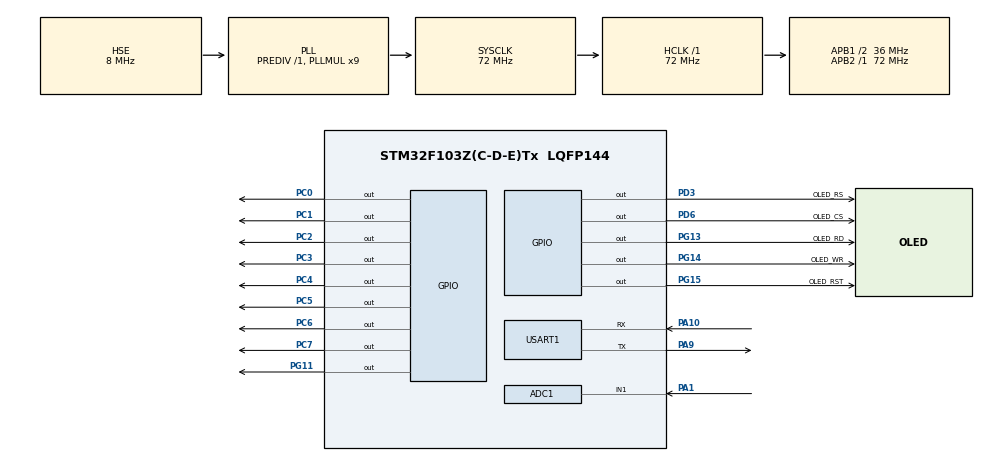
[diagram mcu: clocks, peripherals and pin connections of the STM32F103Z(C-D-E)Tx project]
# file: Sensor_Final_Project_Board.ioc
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ADC1.Channel-0\#ChannelRegularConversion=ADC_CHANNEL_1
ADC1.NbrOfConversionFlag=1
ADC1.Rank-0\#ChannelRegularConversion=1
ADC1.SamplingTime-0\#ChannelRegularConversion=ADC_SAMPLETIME_239CYCLES_5
ADC1.master=1
Mcu.Family=STM32F1
Mcu.Name=STM32F103Z(C-D-E)Tx
Mcu.Package=LQFP144
NVIC.PriorityGroup=NVIC_PRIORITYGROUP_4
NVIC.TIM2_IRQn=true\:0\:0\:false\:false\:true\:true\:true\:true
OSC_IN.Mode=HSE-External-Oscillator
OSC_IN.Signal=RCC_OSC_IN
OSC_OUT.Mode=HSE-External-Oscillator
OSC_OUT.Signal=RCC_OSC_OUT
PA1.Signal=ADCx_IN1
PA10.Mode=Asynchronous
PA10.Signal=USART1_RX
PA13.Mode=Serial_Wire
PA13.Signal=SYS_JTMS-SWDIO
PA14.Mode=Serial_Wire
PA14.Signal=SYS_JTCK-SWCLK
PA9.Mode=Asynchronous
PA9.Signal=USART1_TX
PC0.GPIO_Speed=GPIO_SPEED_FREQ_HIGH
PC0.PinState=GPIO_PIN_SET
PC0.Signal=GPIO_Output
PC1.GPIO_Speed=GPIO_SPEED_FREQ_HIGH
PC1.PinState=GPIO_PIN_SET
PC1.Signal=GPIO_Output
PC14-OSC32_IN.Mode=LSE-External-Oscillator
PC14-OSC32_IN.Signal=RCC_OSC32_IN
PC15-OSC32_OUT.Mode=LSE-External-Oscillator
PC15-OSC32_OUT.Signal=RCC_OSC32_OUT
PC2.GPIO_Speed=GPIO_SPEED_FREQ_HIGH
PC2.PinState=GPIO_PIN_SET
PC2.Signal=GPIO_Output
PC3.GPIO_Speed=GPIO_SPEED_FREQ_HIGH
PC3.PinState=GPIO_PIN_SET
PC3.Signal=GPIO_Output
PC4.GPIO_Speed=GPIO_SPEED_FREQ_HIGH
PC4.PinState=GPIO_PIN_SET
PC4.Signal=GPIO_Output
PC5.GPIO_Speed=GPIO_SPEED_FREQ_HIGH
PC5.PinState=GPIO_PIN_SET
PC5.Signal=GPIO_Output
PC6.GPIO_Speed=GPIO_SPEED_FREQ_HIGH
PC6.PinState=GPIO_PIN_SET
PC6.Signal=GPIO_Output
PC7.GPIO_Speed=GPIO_SPEED_FREQ_HIGH
PC7.PinState=GPIO_PIN_SET
PC7.Signal=GPIO_Output
PD3.GPIO_Label=OLED_RS
PD3.GPIO_Speed=GPIO_SPEED_FREQ_HIGH
PD3.PinState=GPIO_PIN_SET
PD3.Signal=GPIO_Output
PD6.GPIO_Label=OLED_CS
PD6.GPIO_Speed=GPIO_SPEED_FREQ_HIGH
PD6.PinState=GPIO_PIN_SET
PD6.Signal=GPIO_Output
PG11.GPIO_ModeDefaultOutputPP=GPIO_MODE_OUTPUT_OD
PG11.GPIO_PuPd=GPIO_NOPULL
PG11.GPIO_Speed=GPIO_SPEED_FREQ_HIGH
PG11.PinState=GPIO_PIN_SET
PG11.Signal=GPIO_Output
PG13.GPIO_Label=OLED_RD
PG13.GPIO_Speed=GPIO_SPEED_FREQ_HIGH
PG13.PinState=GPIO_PIN_SET
PG13.Signal=GPIO_Output
PG14.GPIO_Label=OLED_WR
PG14.GPIO_Speed=GPIO_SPEED_FREQ_HIGH
PG14.PinState=GPIO_PIN_SET
PG14.Signal=GPIO_Output
PG15.GPIO_Label=OLED_RST
PG15.GPIO_Speed=GPIO_SPEED_FREQ_HIGH
PG15.PinState=GPIO_PIN_SET
PG15.Signal=GPIO_Output
ProjectManager.HeapSize=0x200
ProjectManager.StackSize=0x400
ProjectManager.TargetToolchain=STM32CubeIDE
RCC.ADCPresc=RCC_ADCPCLK2_DIV6
RCC.AHBFreq_Value=72000000
RCC.APB1CLKDivider=RCC_HCLK_DIV2
RCC.APB1Freq_Value=36000000
RCC.APB1TimFreq_Value=72000000
RCC.APB2Freq_Value=72000000
RCC.APB2TimFreq_Value=72000000
RCC.HCLKFreq_Value=72000000
RCC.PLLMUL=RCC_PLL_MUL9
RCC.PLLSourceVirtual=RCC_PLLSOURCE_HSE
RCC.RTCClockSelection=RCC_RTCCLKSOURCE_LSE
RCC.SYSCLKFreq_VALUE=72000000
RCC.SYSCLKSource=RCC_SYSCLKSOURCE_PLLCLK
RCC.USBFreq_Value=72000000
SH.ADCx_IN1.0=ADC1_IN1,IN1
TIM2.Period=10000 - 1
TIM2.Prescaler=7200 - 1
USART1.VirtualMode=VM_ASYNC
VP_RTC_VS_RTC_Activate.Mode=RTC_Enabled
VP_TIM2_VS_ClockSourceINT.Mode=Internal
board=custom

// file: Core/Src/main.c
/* USER CODE BEGIN Header */
/**
  ******************************************************************************
  * @file           : main.c
  * @brief          : Main program body
  ******************************************************************************
  * @attention
  *
  * Copyright (c) 2026 STMicroelectronics.
  * All rights reserved.
  *
  * This software is licensed under terms that can be found in the LICENSE file
  * in the root directory of this software component.
  * If no LICENSE file comes with this software, it is provided AS-IS.
  *
  ******************************************************************************
  */
/* USER CODE END Header */
#include "main.h"
#include "adc.h"
#include "rtc.h"
#include "tim.h"
#include "usart.h"
#include "gpio.h"

/* USER CODE BEGIN Includes */
#include "app_task.h"
/* USER CODE END Includes */

/* USER CODE BEGIN PV */
volatile uint8_t g_task_1s_flag = 0;
/* USER CODE END PV */

void SystemClock_Config(void);

int main(void)
{

  /* MCU Configuration--------------------------------------------------------*/

  /* Reset of all peripherals, Initializes the Flash interface and the Systick. */
  HAL_Init();

  /* Configure the system clock */
  SystemClock_Config();

  /* Initialize all configured peripherals */
  MX_GPIO_Init();
  MX_ADC1_Init();
  MX_RTC_Init();
  MX_TIM2_Init();
  MX_USART1_UART_Init();
  /* USER CODE BEGIN 2 */
  APP_UserInit();
  HAL_TIM_Base_Start_IT(&htim2);
  /* USER CODE END 2 */

  /* Infinite loop */
  while (1)
  {
      APP_TaskPoll();
	  if (g_task_1s_flag)
	  {
	      g_task_1s_flag = 0;
	      APP_Task1s();
	  }
  }
}

void SystemClock_Config(void)
{
  RCC_OscInitTypeDef RCC_OscInitStruct = {0};
  RCC_ClkInitTypeDef RCC_ClkInitStruct = {0};
  RCC_PeriphCLKInitTypeDef PeriphClkInit = {0};

  /** Initializes the RCC Oscillators according to the specified parameters
  * in the RCC_OscInitTypeDef structure.
  */
  RCC_OscInitStruct.OscillatorType = RCC_OSCILLATORTYPE_HSE|RCC_OSCILLATORTYPE_LSE;
  RCC_OscInitStruct.HSEState = RCC_HSE_ON;
  RCC_OscInitStruct.HSEPredivValue = RCC_HSE_PREDIV_DIV1;
  RCC_OscInitStruct.LSEState = RCC_LSE_ON;
  RCC_OscInitStruct.HSIState = RCC_HSI_ON;
  RCC_OscInitStruct.PLL.PLLState = RCC_PLL_ON;
  RCC_OscInitStruct.PLL.PLLSource = RCC_PLLSOURCE_HSE;
  RCC_OscInitStruct.PLL.PLLMUL = RCC_PLL_MUL9;
  if (HAL_RCC_OscConfig(&RCC_OscInitStruct) != HAL_OK)
  {
    Error_Handler();
  }

  /** Initializes the CPU, AHB and APB buses clocks
  */
  RCC_ClkInitStruct.ClockType = RCC_CLOCKTYPE_HCLK|RCC_CLOCKTYPE_SYSCLK
                              |RCC_CLOCKTYPE_PCLK1|RCC_CLOCKTYPE_PCLK2;
  RCC_ClkInitStruct.SYSCLKSource = RCC_SYSCLKSOURCE_PLLCLK;
  RCC_ClkInitStruct.AHBCLKDivider = RCC_SYSCLK_DIV1;
  RCC_ClkInitStruct.APB1CLKDivider = RCC_HCLK_DIV2;
  RCC_ClkInitStruct.APB2CLKDivider = RCC_HCLK_DIV1;

  if (HAL_RCC_ClockConfig(&RCC_ClkInitStruct, FLASH_LATENCY_2) != HAL_OK)
  {
    Error_Handler();
  }
  PeriphClkInit.PeriphClockSelection = RCC_PERIPHCLK_RTC|RCC_PERIPHCLK_ADC;
  PeriphClkInit.RTCClockSelection = RCC_RTCCLKSOURCE_LSE;
  PeriphClkInit.AdcClockSelection = RCC_ADCPCLK2_DIV6;
  if (HAL_RCCEx_PeriphCLKConfig(&PeriphClkInit) != HAL_OK)
  {
    Error_Handler();
  }
}

/* USER CODE BEGIN 4 */
void HAL_TIM_PeriodElapsedCallback(TIM_HandleTypeDef *htim)
{
    if (htim->Instance == TIM2)
    {
        g_task_1s_flag = 1;
    }
}
/* USER CODE END 4 */

void Error_Handler(void)
{
  __disable_irq();
  while (1)
  {
  }
}
